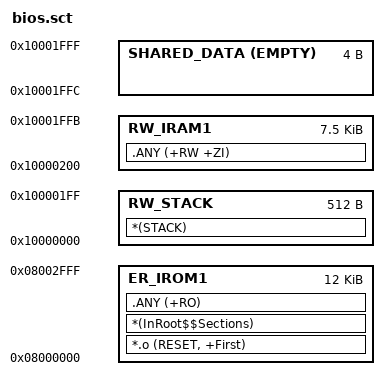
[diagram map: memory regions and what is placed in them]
; *************************************************************
; *** Scatter-Loading Description File generated by uVision ***
; *************************************************************

LR_IROM1 0x08000000 0x00040000      ; load region size_region
{
  ER_IROM1 0x08000000 0x0003000    ; load address = execution address
  {
   *.o (RESET, +First)
   *(InRoot$$Sections)
   .ANY (+RO)
  }
  
  RW_STACK 0x10000000 0x200 	; Stack
  {
    *(STACK)
  }
  
  RW_IRAM1 0x10000200 0x1DFC  ; RW data
  {
   .ANY (+RW +ZI)
  }
  
  SHARED_DATA 0x10001FFC EMPTY 4 {}
}

